CM_ "IMPORT _toyota_2017.dbc"
CM_ "IMPORT _comma.dbc"

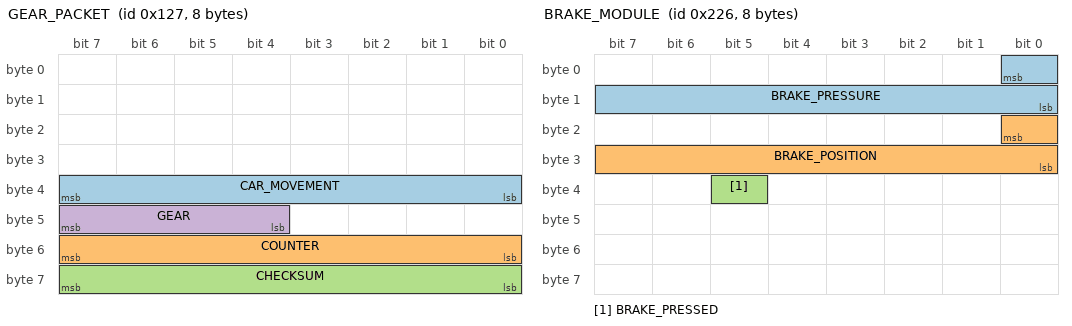
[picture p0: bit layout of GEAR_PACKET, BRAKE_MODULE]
BO_ 295 GEAR_PACKET: 8 XXX
 SG_ CAR_MOVEMENT : 39|8@0- (1,0) [0|255] "" XXX
 SG_ COUNTER : 55|8@0+ (1,0) [0|255] "" XXX
 SG_ CHECKSUM : 63|8@0+ (1,0) [0|255] "" XXX
 SG_ GEAR : 47|4@0+ (1,0) [0|15] "" XXX

BO_ 550 BRAKE_MODULE: 8 XXX
 SG_ BRAKE_PRESSURE : 0|9@0+ (1,0) [0|511] "" XXX
 SG_ BRAKE_POSITION : 16|9@0+ (1,0) [0|511] "" XXX
 SG_ BRAKE_PRESSED : 37|1@0+ (1,0) [0|1] "" XXX

BO_ 581 GAS_PEDAL: 8 XXX
 SG_ GAS_PEDAL : 23|8@0+ (0.005,0) [0|1] "" XXX

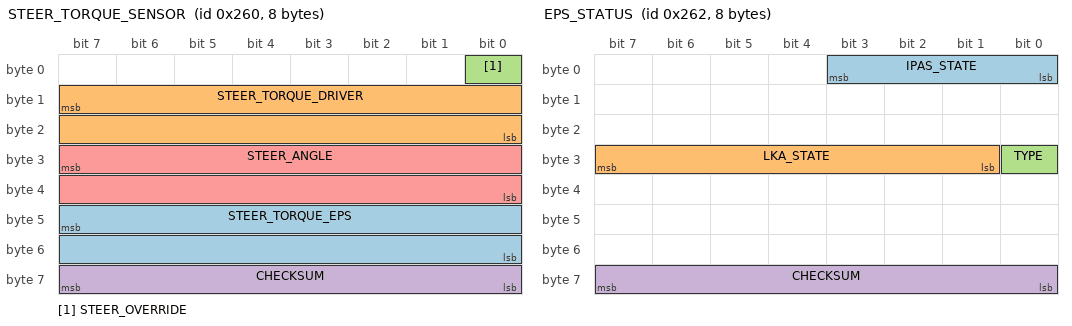
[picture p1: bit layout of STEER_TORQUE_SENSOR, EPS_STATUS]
BO_ 608 STEER_TORQUE_SENSOR: 8 XXX
 SG_ STEER_TORQUE_EPS : 47|16@0- (0.66,0) [-20000|20000] "" XXX
 SG_ STEER_TORQUE_DRIVER : 15|16@0- (1,0) [-32768|32767] "" XXX
 SG_ STEER_OVERRIDE : 0|1@0+ (1,0) [0|1] "" XXX
 SG_ CHECKSUM : 63|8@0+ (1,0) [0|255] "" XXX
 SG_ STEER_ANGLE : 31|16@0- (0.0573,0) [-500|500] "" XXX

BO_ 35 SECONDARY_STEER_ANGLE: 8 XXX
 SG_ ZORRO_STEER : 7|24@0- (0.004901594652,0) [-500|500] "" XXX

BO_ 610 EPS_STATUS: 8 EPS
 SG_ IPAS_STATE : 3|4@0+ (1,0) [0|15] "" XXX
 SG_ LKA_STATE : 31|7@0+ (1,0) [0|127] "" XXX
 SG_ TYPE : 24|1@0+ (1,0) [0|1] "" XXX
 SG_ CHECKSUM : 63|8@0+ (1,0) [0|255] "" XXX

BO_ 1083 AUTOPARK_STATUS: 8 IPAS
 SG_ STATE : 7|4@0+ (1,0) [0|15] "" XXX

CM_ SG_ 550 BRAKE_PRESSURE "seems prop to pedal force";
CM_ SG_ 550 BRAKE_POSITION "seems proportional to pedal displacement, unclear the max value of 0x1c8";
CM_ SG_ 581 GAS_PEDAL "it seems slightly filtered";
CM_ SG_ 610 TYPE "seems 1 on Corolla, 0 on all others";
CM_ SG_ 1083 STATE "when the dashboard button is pressed, the value changes from zero to non-zero";
VAL_ 295 GEAR 0 "P" 1 "R" 2 "N" 3 "D" 4 "B";
VAL_ 610 IPAS_STATE 5 "override" 3 "enabled" 1 "disabled";
VAL_ 610 LKA_STATE 25 "temporary_fault" 9 "temporary_fault2" 5 "active" 1 "standby";
